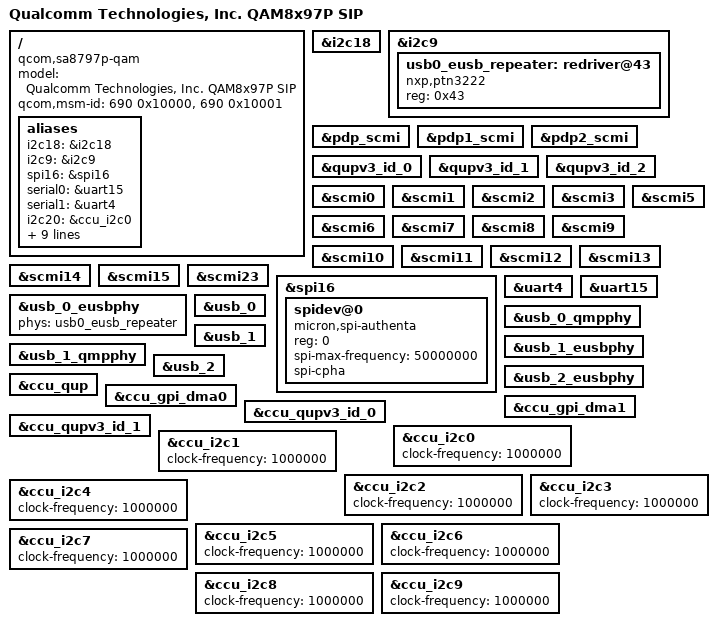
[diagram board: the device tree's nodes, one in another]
// SPDX-License-Identifier: BSD-3-Clause
/*
 * Copyright (c) Qualcomm Technologies, Inc. and/or its subsidiaries.
 */

/ {
	model = "Qualcomm Technologies, Inc. QAM8x97P SIP";
	compatible = "qcom,sa8797p-qam","qcom,sa8797p";
	qcom,msm-id = <690 0x10000>, <690 0x10001>;

	aliases {
		i2c18 = &i2c18;
		i2c9 = &i2c9;
		spi16 = &spi16;
		serial0 = &uart15;
		serial1 = &uart4;
		i2c20 = &ccu_i2c0;
		i2c21 = &ccu_i2c1;
		i2c22 = &ccu_i2c2;
		i2c23 = &ccu_i2c3;
		i2c24 = &ccu_i2c4;
		i2c25 = &ccu_i2c5;
		i2c26 = &ccu_i2c6;
		i2c27 = &ccu_i2c7;
		i2c28 = &ccu_i2c8;
		i2c29 = &ccu_i2c9;
	};
};

&i2c18 {
	status = "okay";
};

&i2c9 {
	status = "okay";

	#address-cells = <1>;
	#size-cells = <0>;

	usb0_eusb_repeater: redriver@43 {
		compatible = "nxp,ptn3222";
		reg = <0x43>;
		#phy-cells = <0>;
	};
};

&pdp_scmi {
	status = "okay";
};

&pdp1_scmi {
	status = "okay";
};

&pdp2_scmi {
	status = "okay";
};

&qupv3_id_0 {
	status = "okay";
};

&qupv3_id_1 {
	status = "okay";
};

&qupv3_id_2 {
	status = "okay";
};

&scmi0 {
	status = "okay";
};

&scmi1 {
	status = "okay";
};

&scmi2 {
	status = "okay";
};

&scmi3 {
	status = "okay";
};

&scmi5 {
	status = "okay";
};

&scmi6 {
	status = "okay";
};

&scmi7 {
	status = "okay";
};

&scmi8 {
	status = "okay";
};

&scmi9 {
	status = "okay";
};

&scmi10 {
	status = "okay";
};

&scmi11 {
	status = "okay";
};

&scmi12 {
	status = "okay";
};

&scmi13 {
	status = "okay";
};

&scmi14 {
	status = "okay";
};

&scmi15 {
	status = "okay";
};

&scmi23 {
	status = "okay";
};

&spi16 {
	status = "okay";
	spidev@0 {
		compatible = "micron,spi-authenta";
		reg = <0>;
		spi-max-frequency = <50000000>;
		spi-cpha;
	};
};

&uart4 {
	status = "okay";
};

&uart15 {
	status = "okay";
};

&usb_0_eusbphy {
	status = "okay";
	phys = <&usb0_eusb_repeater>;
};

&usb_0_qmpphy {
	status = "okay";
};

&usb_0 {
	status = "okay";
};

&usb_1_eusbphy {
	status = "okay";
};

&usb_1_qmpphy {
	status = "okay";
};

&usb_1 {
	status = "okay";
};

&usb_2_eusbphy {
	status = "okay";
};

&usb_2 {
	status = "okay";
};


&ccu_qup {
	status = "okay";
};

&ccu_gpi_dma0 {
	status = "okay";
};

&ccu_gpi_dma1 {
	status = "okay";
};

&ccu_qupv3_id_0 {
	status = "okay";
};

&ccu_qupv3_id_1 {
	status = "okay";
};

&ccu_i2c0 {
	status = "okay";
	clock-frequency = <1000000>;
};

&ccu_i2c1 {
	status = "okay";
	clock-frequency = <1000000>;
};

&ccu_i2c2 {
	status = "okay";
	clock-frequency = <1000000>;
};

&ccu_i2c3 {
	status = "okay";
	clock-frequency = <1000000>;
};

&ccu_i2c4 {
	status = "okay";
	clock-frequency = <1000000>;
};

&ccu_i2c5 {
	status = "okay";
	clock-frequency = <1000000>;
};

&ccu_i2c6 {
	status = "okay";
	clock-frequency = <1000000>;
};

&ccu_i2c7 {
	status = "okay";
	clock-frequency = <1000000>;
};

&ccu_i2c8 {
	status = "okay";
	clock-frequency = <1000000>;
};

&ccu_i2c9 {
	status = "okay";
	clock-frequency = <1000000>;
};
